# M55M1 register map
File version: 1.0
Registers are 32-bit, read-write, reset 0x0 unless marked. A register's access mark holds for its fields unless they carry their own. Offsets are from the block's base; [hi:lo] are bit positions; {n}, {i} and the like mark numbered series; 'fields as' and 'values as' point back to an identical list.

## LPTMR01 — LPTMR Register Map
Base 0x40440000
Same registers: LPTMR01_NS 0x50440000
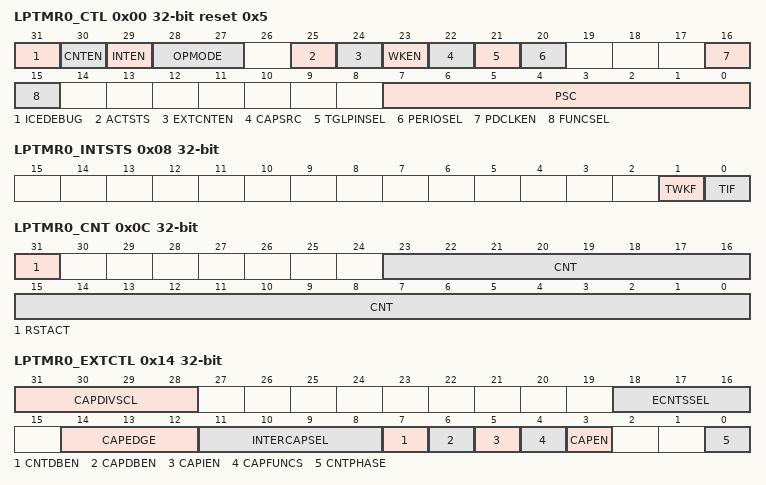
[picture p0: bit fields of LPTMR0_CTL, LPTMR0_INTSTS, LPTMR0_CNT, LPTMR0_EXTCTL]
0x00 LPTMR0_CTL reset 0x5 — LPTMR0 Control Register
  [31] ICEDEBUG — ICE Debug Mode Acknowledge Disable Bit (Write Protect). TIMER counter will keep going no matter CPU is held by ICE or not. Note: This bit is write protected. Refer to the SYS_REGLCTL register.
    0=ICE debug mode acknowledgement effects TIMER counting; 1=ICE debug mode acknowledgement Disabled
  [30] CNTEN — Low Power Timer Counting Enable Bit. Note 3: Set enable/disable this bit needs 2 * LPTMR_CLK period to become active, user can read ACTSTS (LPTMRx_CTL[25]) to check enable/disable command is completed or not.
    0=Stops/Suspends counting; 1=Starts counting
  [29] INTEN — Low Power Timer Interrupt Enable Bit. Note: If this bit is enabled, when the low power timer time-out interrupt flag TIF is set to 1, the low power timer interrupt signal is generated and inform to CPU.
    0=Low Power Timer time-out interrupt Disabled; 1=Low Power Timer time-out interrupt Enabled
  [28:27] OPMODE — Low Power Timer Counting Mode Select
    0=The low power timer controller is operated in One-shot mode; 1=The low power timer controller is operated in Periodic mode; 2=The low power timer controller is operated in Toggle-output mode; 3=The low power timer controller is operated in Continuous Counting mode
  [25] ACTSTS ro — Low Power Timer Active Status Bit (Read Only). This bit indicates the 24-bit up counter status. Note: This bit may active when CNT 0 transition to CNT 1.
    0=24-bit up counter is not active; 1=24-bit up counter is active
  [24] EXTCNTEN — Event Counter Mode Enable Bit. This bit is for external counting pin function enabled. Note: When timer is used as an event counter, this bit should be set to 1.
    0=Event counter mode Disabled; 1=Event counter mode Enabled
  [23] WKEN — Wake-up Function Enable Bit. If this bit is set to 1, while timer interrupt flag TIF (LPTMRx_INTSTS[0]) is 1 and INTEN (LPTMRx_CTL[29]) is enabled, the low power timer interrupt signal will generate a wake-up trigger event to CPU.
    0=Wake-up function Disabled if timer interrupt signal generated; 1=Wake-up function Enabled if timer interrupt signal generated
  [22] CAPSRC — Capture Pin Source Selection
    0=Capture Function source is from LPTMRx_EXT (x= 0~1) pin; 1=Capture Function source is from internal ACMP output signal
  [21] TGLPINSEL — Toggle-output Pin Select
    0=Toggle mode output to LPTMRx (Low Power Timer Event Counter Pin); 1=Toggle mode output to LPTMRx_EXT (Low Power Timer External Capture Pin)
  [20] PERIOSEL — Periodic Mode Behavior Selection Enable Bit. If updated CMPDAT value CNT, CNT will be reset to default value.
    0=The behavior selection in periodic mode is Disabled; 1=The behavior selection in periodic mode is Enabled
  [16] PDCLKEN — Power-down Engine Clock Enable
    0=Disable engine clock in power-down mode; 1=Enable engine clock in power-down mode
  [15] FUNCSEL — Function Selection
    0=Low Power Timer controller is used as timer function; 1=Low Power Timer controller is used as PWM function
  [7:0] PSC — Prescale Counter. Note: Update prescale counter value will reset internal 8-bit prescale counter and 24-bit up counter value.
0x04 LPTMR0_CMP — LPTMR0 Comparator Register
  [23:0] CMPDAT — Low Power Timer Comparator Value. CMPDAT is a 24-bit compared value register. When the internal 24-bit up counter value is equal to CMPDAT value, the TIF (LPTMRx_INTSTS[0] Low Power Timer Interrupt Flag) will set to 1. Note 1: Never write 0x0 or 0x1 in CMPDAT field, or the core will run into unknown state. Note 2: When timer is operating at continuous counting mode, the 24-bit up counter will keep counting continuously even if user writes a new value into CMPDAT field. But if timer is operating at other modes, the 24-bit up counter will restart counting from 0 and using newest CMPDAT value to be the low power timer compared value while user writes a new value into CMPDAT field.
0x08 LPTMR0_INTSTS — LPTMR0 Interrupt Status Register
  [1] TWKF — Low Power Timer Wake-up Flag. This bit indicates the interrupt wake-up flag status of timer. Note: This bit is cleared by writing 1 to it.
    0=Low Power Timer does not cause CPU wake-up; 1=CPU wake-up from Idle or Power-down mode if timer time-out interrupt signal generated
  [0] TIF — Low Power Timer Interrupt Flag. This bit indicates the interrupt flag status of Low Power Timer while 24-bit timer up counter CNT (LPTMRx_CNT[23:0]) value reaches to CMPDAT (LPTMRx_CMP[23:0]) value. Note: This bit is cleared by writing 1 to it.
    0=No effect; 1=CNT value matches the CMPDAT value
0x0C LPTMR0_CNT — LPTMR0 Data Register
  [31] RSTACT ro — Low Power Timer Data Register Reset Active (Read Only). This bit indicates if the counter reset operation active. When user writes this CNT register, low power timer starts to reset its internal 24-bit timer up-counter to 0 and reload 8-bit pre-scale counter. At the same time, timer set this flag to 1 to indicate the counter reset operation is in progress. Once the counter reset operation done, low power timer clear this bit to 0 automatically.
    0=Reset operation is done; 1=Reset operation triggered by writing LPTMRx_CNT is in progress
  [23:0] CNT — Low Power Timer Data Register. Read operation. Read this register to get CNT value. For example: If EXTCNTEN (LPTMRx_CTL[24]) is 0, user can read CNT value for getting current 24-bit counter value. If EXTCNTEN (LPTMRx_CTL[24]) is 1, user can read CNT value for getting current 24-bit event input counter value. Write operation. Writing any value to this register will reset current CNT value to 0 and reload internal 8-bit prescale counter.
0x10 LPTMR0_CAP ro — LPTMR0 Capture Data Register
  [23:0] CAPDAT — Low Power Timer Capture Data Register. When CAPEN (LPTMRx_EXTCTL[3]) bit is set, CAPFUNCS (LPTMRx_EXTCTL[4]) bit is 0, and a transition on LPTMRx_EXT pin matched the CAPEDGE (LPTMRx_EXTCTL[14:12]) setting, CAPIF (LPTMRx_EINTSTS[0]) will set to 1 and the current timer counter value CNT (LPTMRx_CNT[23:0]) will be auto-loaded into this CAPDAT field.
0x14 LPTMR0_EXTCTL — LPTMR0 External Control Register
  [31:28] CAPDIVSCL — Low Power Timer Capture Source Divider Scale. This bits indicate the divide scale for capture source divider. Note: Set INTERCAPSEL (LPTMRx_EXTCTL[11:8]) and CAPSRC (LPTMRx_CTL[22]) to select capture source.
    0=Capture source/1; 1=Capture source/2; 2=Capture source/4; 3=Capture source/8; 4=Capture source/16; 5=Capture source/32; 6=Capture source/64; 7=Capture source/128; 8=Capture source/256
  [18:16] ECNTSSEL — Event Counter Source Selection to Trigger Event Counter Function
    0=Event Counter input source is from external LPTMRx (x= 0~1) pin; {v}=Event Counter input source is from internal ACMP{v-2} output signal (v=2..5)
  [14:12] CAPEDGE — Low Power Timer External Capture Pin Edge Detect. When first capture event is generated, the CNT (LPTMRx_CNT[23:0]) will be reset to 0 and first CAPDAT (LPTMRx_CAP[23:0]) should be to 0. Note: Set CAPSRC (LPTMRx_CTL[22]) and INTERCAPSEL (LPTMRx_EXTCTL[11:8]) to select capture source.
    0=Capture event occurred when detect falling edge transfer on LPTMRx_EXT (x= 0~1) pin; 1=Capture event occurred when detect rising edge transfer on LPTMRx_EXT (x= 0~1) pin; 2=Capture event occurred when detect both falling and rising edge transfer on LPTMRx_EXT (x= 0~1) pin, and first capture event occurred at falling edge transfer; 3=Capture event occurred when detect both rising and falling edge transfer on LPTMRx_EXT (x= 0~1) pin, and first capture event occurred at rising edge transfer; 6=First capture event occurred at falling edge, follows capture events are at rising edge transfer on LPTMRx_EXT (x= 0~1) pin; 7=First capture event occurred at rising edge, follows capture events are at falling edge transfer on LPTMRx_EXT (x= 0~1) pin
  [11:8] INTERCAPSEL — Internal Capture Source Select. Note: these bits only available when CAPSRC (LPTMRx_CTL[22]) is 1.
    0=Capture Function source is from internal ACMP0 output signal; 1=Capture Function source is from internal ACMP1 output signal; 7=Capture Function source is from internal ACMP2 output signal; 8=Capture Function source is from internal ACMP3 output signal
  [7] CNTDBEN — Low Power Timer Counter Pin De-bounce Enable Bit. Note: If this bit is enabled, the edge detection of LPTMRx pin is detected with de-bounce circuit.
    0=LPTMRx (x= 0~1) pin de-bounce Disabled; 1=LPTMRx (x= 0~1) pin de-bounce Enabled
  [6] CAPDBEN — Low Power Timer External Capture Pin De-bounce Enable Bit. Note: If this bit is enabled, the edge detection of LPTMRx_EXT pin or ACMP output is detected with de-bounce circuit.
    0=LPTMRx_EXT (x= 0~1) pin de-bounce or ACMP output de-bounce Disabled; 1=LPTMRx_EXT (x= 0~1) pin de-bounce or ACMP output de-bounce Enabled
  [5] CAPIEN — Low Power Timer External Capture Interrupt Enable Bit
    0=LPTMRx_EXT (x= 0~1) pin, ACMP, internal clock, or external clock detection Interrupt Disabled; 1=LPTMRx_EXT (x= 0~1) pin, ACMP, internal clock, or external clock detection Interrupt Enabled
  [4] CAPFUNCS — Capture Function Selection
    0=External Capture Mode Enabled; 1=External Reset Mode Enabled
  [3] CAPEN — Low Power Timer Capture Enable Bit. This bit enables the capture input function. Note: When CAPEN is 1, user can set INTERCAPSEL (LPTMRx_EXTCTL [11:8]) to select capture source.
    0=Capture source Disabled; 1=Capture source Enabled
  [0] CNTPHASE — Low Power Timer External Count Phase
    0=A falling edge of external counting pin will be counted; 1=A rising edge of external counting pin will be counted
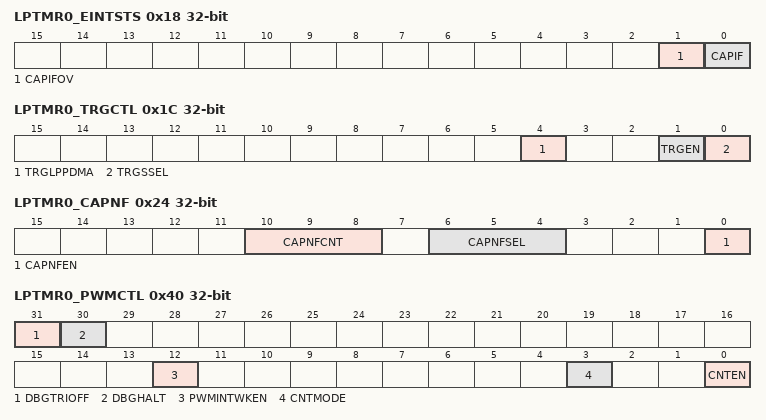
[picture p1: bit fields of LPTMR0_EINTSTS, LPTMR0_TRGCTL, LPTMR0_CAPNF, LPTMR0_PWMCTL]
0x18 LPTMR0_EINTSTS — LPTMR0 External Interrupt Status Register
  [1] CAPIFOV ro — Capture Latch Interrupt Flag Overrun Status (Read Only). Note: This bit will be cleared automatically when user clear corresponding CAPIF.
    0=Capture latch happened when the corresponding CAPIF is 0; 1=Capture latch happened when the corresponding CAPIF is 1
  [0] CAPIF — Low Power Timer External Capture Interrupt Flag. This bit indicates the low power timer external capture interrupt flag status. Note 3: There is a new incoming capture event detected before CPU clearing the CAPIF status. If the above condition occurred, the Low Power Timer will keep register LPTMRx_CAP unchanged and drop the new capture value.
    0=LPTMRx_EXT (x= 0~1) pin, ACMP, internal clock, or external clock interrupt did not occur; 1=LPTMRx_EXT (x= 0~1) pin, ACMP, internal clock, or external clock interrupt occurred
0x1C LPTMR0_TRGCTL — LPTMR0 Trigger Control Register
  [4] TRGLPPDMA — Trigger LPPDMA Enable Bit. If this bit is set to 1, each timer time-out event or capture event can be triggered LPPDMA transfer.
    0=Low Power Timer interrupt trigger LPPDMA Disabled; 1=Low Power Timer interrupt trigger LPPDMA Enabled
  [1] TRGEN — Trigger Low power IPs Enable Bit. If this bit is set to 1, each timer time-out event or capture event can trigger Low Power IPs.
    0=Low Power Timer interrupt trigger Low Power IPs Disabled; 1=Low Power Timer interrupt trigger Low Power IPs Enabled
  [0] TRGSSEL — Trigger Source Select Bit. This bit is used to select internal trigger source is from timer time-out interrupt signal or capture interrupt signal.
    0=Time-out interrupt signal is used to internal trigger LPADC0, LPI2C0, LPSPI0, LPUART, , CCAP Motion detector and LPPDMA; 1=Capture interrupt signal is used to internal trigger LPADC0, LPI2C0, LPSPI0, LPUART, , CCAP Motion detector and LPPDMA
0x24 LPTMR0_CAPNF — LPTMR0 Capture Input Noise Filter Register
  [10:8] CAPNFCNT — Capture Edge Detector Noise Filter Count. These bits control the capture filter counter to count from 0 to CAPNFCNT.
  [6:4] CAPNFSEL — Capture Edge Detector Noise Filter Clock Selection
    0=Noise filter clock is ECLKx; 1=Noise filter clock is ECLKx/2; 2=Noise filter clock is ECLKx/4; 3=Noise filter clock is ECLKx/8; 4=Noise filter clock is ECLKx/16; 5=Noise filter clock is ECLKx/32; 6=Noise filter clock is ECLKx/64; 7=Noise filter clock is ECLKx/128
  [0] CAPNFEN — Capture Noise Filter Enable
    0=Capture Noise Filter function Disabled; 1=Capture Noise Filter function Enabled
0x40 LPTMR0_PWMCTL — LPTMR0 PWM Control Register
  [31] DBGTRIOFF — ICE Debug Mode Acknowledge Disable Bit (Write Protect). PWM output pin will keep output no matter ICE debug mode acknowledged or not. Note: This bit is write protected. Refer to SYS_REGLCTL control register.
    0=ICE debug mode acknowledgement effects PWM output; 1=ICE debug mode acknowledgement disabled
  [30] DBGHALT — ICE Debug Mode Counter Halt (Write Protect). If debug mode counter halt is enabled, PWM counter will keep current value until exit ICE debug mode. Note: This bit is write protected. Refer to SYS_REGLCTL control register.
    0=ICE debug mode counter halt Disabled; 1=ICE debug mode counter halt Enabled
  [12] PWMINTWKEN — PWM Interrupt Wake-up Enable Bit. If PWM interrupt occurs when chip is in Power-down mode, PWMINTWKEN can determine whether chip wake-up occurs or not.
    0=PWM interrupt wake-up Disabled; 1=PWM interrupt wake-up Enabled
  [3] CNTMODE — PWM Counter Mode
    0=Auto-reload mode; 1=One-shot mode
  [0] CNTEN — PWM Counter Enable Bit
    0=PWM counter and clock prescale Stop Running; 1=PWM counter and clock prescale Start Running
0x44 LPTMR0_PWMCLKPSC — LPTMR0 PWM Counter Clock Pre-scale Register
  [7:0] CLKPSC — PWM Counter Clock Pre-scale. The active clock of PWM counter is decided by counter clock prescale and divided by (CLKPSC + 1). If CLKPSC is 0, then there is no scaling in PWM counter clock source.
0x48 LPTMR0_PWMCNTCLR — LPTMR0 PWM Clear Counter Register
  [0] CNTCLR — Clear PWM Counter Control Bit. It is automatically cleared by hardware.
    0=No effect; 1=Clear 16-bit PWM counter to 0x0000 in up count type
0x4C LPTMR0_PWMPERIOD
  [15:0] PERIOD — PWM Period Register. In up count type: PWM counter counts from 0 to PERIOD, and restarts from 0. In up count type:
0x50 LPTMR0_PWMCMPDAT — LPTMR0 PWM Comparator Register
  [15:0] CMP — PWM Comparator Register. PWM CMP is used to compare with PWM CNT to generate PWM output waveform, interrupt events and trigger EADC and PDMA start conversion.
0x54 LPTMR0_PWMCNT ro — LPTMR0 PWM Counter Register
  [15:0] CNT — PWM Counter Value Register (Read Only). User can monitor CNT to know the current counter value in 16-bit period counter.
0x58 LPTMR0_PWMPOLCTL — LPTMR0 PWM Pin Output Polar Control Register
  [0] PINV — PWMx Output Pin Polar Control Bit. The bit is used to control polarity state of PWMx_OUT pin. Note: Set POSEL (LPTMRx_PWMPOCTL[8]) to select LPTMRx or LPTMRx_EXT as PWMx output pin.
    0=PWMx_OUT pin polar inverse Disabled; 1=PWMx_OUT polar inverse Enabled
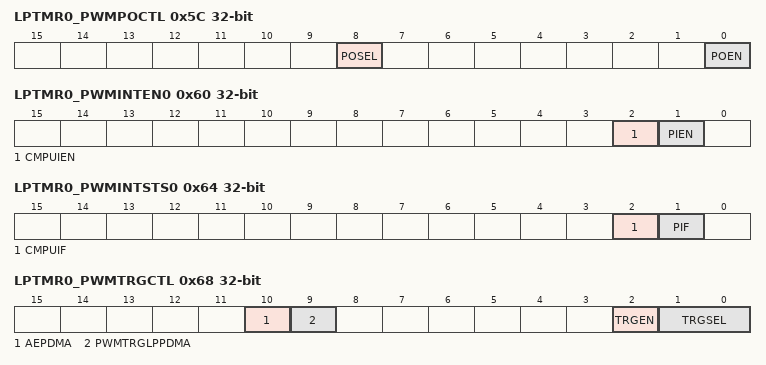
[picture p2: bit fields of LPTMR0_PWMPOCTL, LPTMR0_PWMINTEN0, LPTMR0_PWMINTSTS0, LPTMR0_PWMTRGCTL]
0x5C LPTMR0_PWMPOCTL — LPTMR0 PWM Pin Output Control Register
  [8] POSEL — PWM Output Pin Select
    0=PWMx_OUT pin is LPTMRx; 1=PWMx_OUT pin is LPTMRx_EXT
  [0] POEN — PWMx Output Pin Enable Bit. Note: Set POSEL (LPTMRx_PWMPOCTL[8]) to select LPTMRx or LPTMRx_EXT as PWMx output pin.
    0=PWMx_OUT pin at tri-state mode; 1=PWMx_OUT pin in output mode
0x60 LPTMR0_PWMINTEN0 — LPTMR0 PWM Interrupt Enable Register 0
  [2] CMPUIEN — PWM Compare Up Count Interrupt Enable Bit
    0=Compare up count interrupt Disabled; 1=Compare up count interrupt Enabled
  [1] PIEN — PWM Period Point Interrupt Enable Bit
    0=Period point interrupt Disabled; 1=Period point interrupt Enabled
0x64 LPTMR0_PWMINTSTS0 — LPTMR0 PWM Interrupt Status Register 0
  [2] CMPUIF — PWM Compare Up Count Interrupt Flag. This bit is set by hardware when LPTMRx_PWM counter in up count direction and reaches CMP. Note: If CMP equal to PERIOD, there is no CMPUIF flag in up count type. Note 2: This bit is cleared by writing 1 to it.
  [1] PIF — PWM Period Point Interrupt Flag. This bit is set by hardware when LPTMRx_PWM counter reaches PERIOD. Note: This bit is cleared by writing 1 to it.
0x68 LPTMR0_PWMTRGCTL — LPTMR0 PWM Trigger Control Register
  [10] AEPDMA — Accumulator Every IFACNT LPPDMA Mode Enable Bit. If this bit is set to 1, PWM can trigger LPPDMA in every duty when user uses Accumulator PDMA Function. Note: User should set APDMAEN to 1 first when using this mode.
    0=Trigger LPPDMA Accumulator Mode Disabled; 1=Trigger LPPDMA Accumulator Mode Enabled
  [9] PWMTRGLPPDMA — PWM Counter Event Trigger LPPDMA Conversion Enable Bit. If this bit is set to 1, PWM can trigger LPPDMA conversion. Note: Set TRGSEL (LPTMRx_PWMTRGCTL[1:0]) to select PWM trigger conversion source. Note: TRGEN (LPTMRx_PWMTRGCTL[2]) is needed to be set to 1.
    0=PWM trigger LPPDMA Disabled; 1=PWM trigger LPPDMA Enabled
  [2] TRGEN — Trigger Low power IPs Enable Bit. If this bit is set to 1, Low Power Timer PWM can trigger Low Power IPs.
    0=Low Power Timer PWM counter event trigger Low Power IPs Disabled; 1=Low Power Timer PWM counter event trigger Low Power IPs Enabled
  [1:0] TRGSEL — PWM Counter Event Source Select to Trigger Conversion. Note: Low Power Timer PWM counter event can trigger LPADC0, LPI2C0, LPSPI0, LPUART, CCAP Motion detection detector and LPPDMA.
    0=Trigger conversion at period point (PIF); 1=Trigger conversion at compare up count point (CMPUIF); 2=Trigger conversion at period or compare up count point (PIF or CMPUIF)
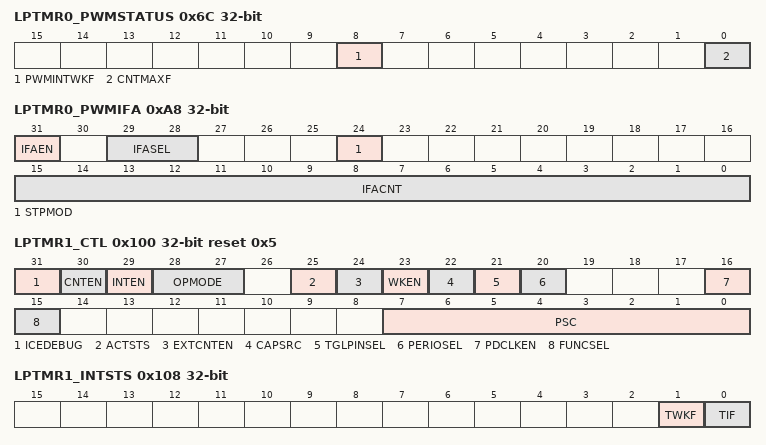
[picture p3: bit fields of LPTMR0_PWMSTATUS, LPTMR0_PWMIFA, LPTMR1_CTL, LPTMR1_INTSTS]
0x6C LPTMR0_PWMSTATUS
  [8] PWMINTWKF — PWM Interrupt Wake-up Flag. Note: This bit is cleared by writing 1 to it.
    0=PWM interrupt wake-up has not occurred; 1=PWM interrupt wake-up has occurred
  [0] CNTMAXF — PWM Counter Equal to 0xFFFF Flag. Note: This bit is cleared by writing 1 to it.
    0=The PWM counter value never reached its maximum value 0xFFFF; 1=The PWM counter value has reached its maximum value
0x70 LPTMR0_PWMPBUF ro — LPTMR0 PWM Period Buffer Register
  [15:0] PBUF — PWM Period Buffer Register (Read Only). Used as PERIOD active register.
0x74 LPTMR0_PWMCMPBUF ro — LPTMR0 PWM Comparator Buffer Register
  [15:0] CMPBUF — PWM Comparator Buffer Register (Read Only). Used as CMP active register.
0xA8 LPTMR0_PWMIFA — LPTMR0 PWM Interrupt Flag Accumulator Register
  [31] IFAEN — PWM Interrupt Flag Accumulator Enable Bit
    0=PWM interrupt flag accumulator function Disabled; 1=PWM interrupt flag accumulator function Enabled
  [29:28] IFASEL — PWM Interrupt Flag Accumulator Source Select
    1=Accumulate at each PWM period point; 2=Accumulate at each PWM up-count compared point
  [24] STPMOD — PWM Accumulator Stop Mode Enable Bit
    0=PWM interrupt accumulator event to stop counting Disabled; 1=PWM interrupt accumulator event to stop counting Enabled
  [15:0] IFACNT — PWM Interrupt Flag Accumulator Counter. This field sets the count number which defines (IFACNT+1) times of specify PWM interrupt occurs to set IFAIF bit to request the PWM accumulator interrupt. PWM accumulator flag (IFAIF) will be set in every (IFACNT+1) times during the the PWM counter operation.
0xAC LPTMR0_PWMAINTSTS — LPTMR0 PWM Accumulator Interrupt Flag Register
  [0] IFAIF — PWM Interrupt Flag Accumulator Interrupt Flag. This bit is set by hardware when the accumulator value reaches (IFACNT+1). Note 1: This bit is cleared by writing 1 to it. Note 2: If APDMAEN (LPTMRx_PWMAPDMACTL[0]) is set, this bit will be auto clear after PDMA transfer done.
0xB0 LPTMR0_PWMAINTEN — LPTMR0 PWM Accumulator Interrupt Enable Register
  [0] IFAIEN — PWM Interrupt Flag Accumulator Interrupt Enable Bit
    0=Interrupt Flag Accumulator interrupt Disabled; 1=Interrupt Flag Accumulator interrupt Enabled
0xB4 LPTMR0_PWMAPDMACTL — LPTMR0 PWM Accumulator LPPDMA Control Register
  [0] APDMAEN — PWM Accumulator LPPDMA Enable Bit
    0=PWM interrupt accumulator event to trigger LPPDMA transfer Disabled; 1=PWM interrupt accumulator event to trigger LPPDMA transfer Enabled
0x100 LPTMR1_CTL reset 0x5 — LPTMR1 Control Register
  fields as LPTMR0_CTL
0x104 LPTMR1_CMP — LPTMR1 Comparator Register
  fields as LPTMR0_CMP
0x108 LPTMR1_INTSTS — LPTMR1 Interrupt Status Register
  fields as LPTMR0_INTSTS
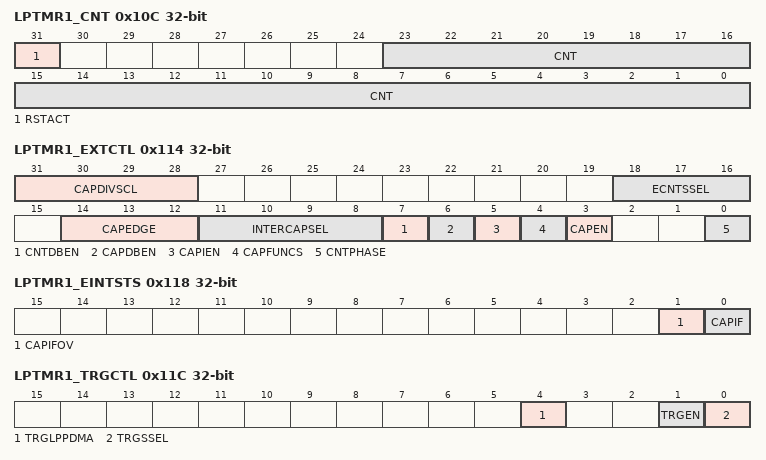
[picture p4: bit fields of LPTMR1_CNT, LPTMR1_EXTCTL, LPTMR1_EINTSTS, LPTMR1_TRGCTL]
0x10C LPTMR1_CNT — LPTMR1 Data Register
  fields as LPTMR0_CNT
0x110 LPTMR1_CAP ro — LPTMR1 Capture Data Register
  fields as LPTMR0_CAP
0x114 LPTMR1_EXTCTL — LPTMR1 External Control Register
  fields as LPTMR0_EXTCTL
0x118 LPTMR1_EINTSTS — LPTMR1 External Interrupt Status Register
  fields as LPTMR0_EINTSTS
0x11C LPTMR1_TRGCTL — LPTMR1 Trigger Control Register
  fields as LPTMR0_TRGCTL
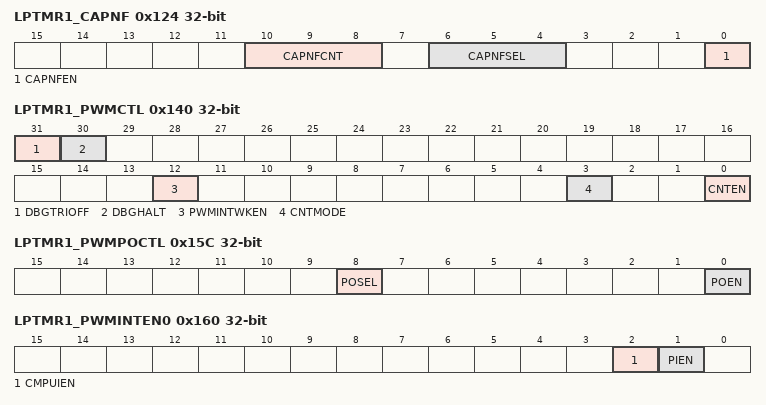
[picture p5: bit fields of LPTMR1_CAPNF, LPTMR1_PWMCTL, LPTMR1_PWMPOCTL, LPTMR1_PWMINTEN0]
0x124 LPTMR1_CAPNF — LPTMR1 Capture Input Noise Filter Register
  fields as LPTMR0_CAPNF
0x140 LPTMR1_PWMCTL — LPTMR1 PWM Control Register
  fields as LPTMR0_PWMCTL
0x144 LPTMR1_PWMCLKPSC — LPTMR1 PWM Counter Clock Pre-scale Register
  fields as LPTMR0_PWMCLKPSC
0x148 LPTMR1_PWMCNTCLR — LPTMR1 PWM Clear Counter Register
  fields as LPTMR0_PWMCNTCLR
0x14C LPTMR1_PWMPERIOD
  fields as LPTMR0_PWMPERIOD
0x150 LPTMR1_PWMCMPDAT — LPTMR1 PWM Comparator Register
  fields as LPTMR0_PWMCMPDAT
0x154 LPTMR1_PWMCNT ro — LPTMR1 PWM Counter Register
  fields as LPTMR0_PWMCNT
0x158 LPTMR1_PWMPOLCTL — LPTMR1 PWM Pin Output Polar Control Register
  fields as LPTMR0_PWMPOLCTL
0x15C LPTMR1_PWMPOCTL — LPTMR1 PWM Pin Output Control Register
  fields as LPTMR0_PWMPOCTL
0x160 LPTMR1_PWMINTEN0 — LPTMR1 PWM Interrupt Enable Register 0
  fields as LPTMR0_PWMINTEN0
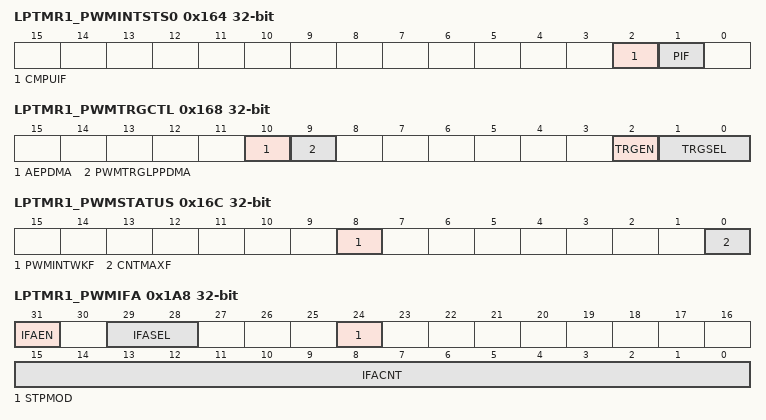
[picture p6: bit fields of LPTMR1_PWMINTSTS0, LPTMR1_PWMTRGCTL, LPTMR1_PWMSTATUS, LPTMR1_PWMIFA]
0x164 LPTMR1_PWMINTSTS0 — LPTMR1 PWM Interrupt Status Register 0
  fields as LPTMR0_PWMINTSTS0
0x168 LPTMR1_PWMTRGCTL — LPTMR1 PWM Trigger Control Register
  fields as LPTMR0_PWMTRGCTL
0x16C LPTMR1_PWMSTATUS
  fields as LPTMR0_PWMSTATUS
0x170 LPTMR1_PWMPBUF ro — LPTMR1 PWM Period Buffer Register
  fields as LPTMR0_PWMPBUF
0x174 LPTMR1_PWMCMPBUF ro — LPTMR1 PWM Comparator Buffer Register
  fields as LPTMR0_PWMCMPBUF
0x1A8 LPTMR1_PWMIFA — LPTMR1 PWM Interrupt Flag Accumulator Register
  fields as LPTMR0_PWMIFA
0x1AC LPTMR1_PWMAINTSTS — LPTMR1 PWM Accumulator Interrupt Flag Register
  fields as LPTMR0_PWMAINTSTS
0x1B0 LPTMR1_PWMAINTEN — LPTMR1 PWM Accumulator Interrupt Enable Register
  fields as LPTMR0_PWMAINTEN
0x1B4 LPTMR1_PWMAPDMACTL — LPTMR1 PWM Accumulator LPPDMA Control Register
  fields as LPTMR0_PWMAPDMACTL
